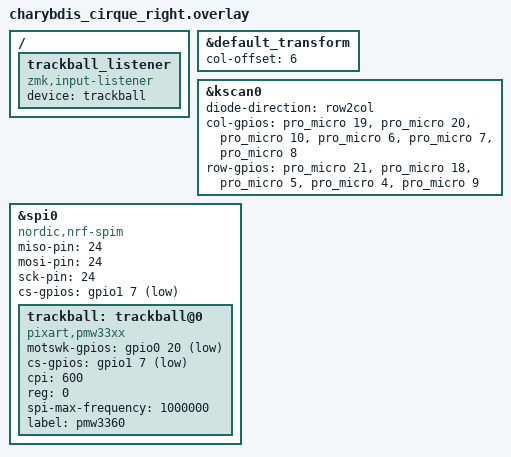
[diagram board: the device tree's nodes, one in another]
#include "charybdis_cirque.dtsi"

&default_transform {
    col-offset = <6>;
};

&kscan0 {
    diode-direction = "row2col";
    col-gpios
		= <&pro_micro 19 (GPIO_ACTIVE_HIGH | GPIO_PULL_DOWN)>
		, <&pro_micro 20 (GPIO_ACTIVE_HIGH | GPIO_PULL_DOWN)>
		, <&pro_micro 10 (GPIO_ACTIVE_HIGH | GPIO_PULL_DOWN)>
		, <&pro_micro 6 (GPIO_ACTIVE_HIGH | GPIO_PULL_DOWN)>
		, <&pro_micro 7 (GPIO_ACTIVE_HIGH | GPIO_PULL_DOWN)>
		, <&pro_micro 8 (GPIO_ACTIVE_HIGH | GPIO_PULL_DOWN)>
    ;
    row-gpios
		 	= <&pro_micro 21 GPIO_ACTIVE_HIGH>
		 	, <&pro_micro 18 GPIO_ACTIVE_HIGH>
		 	, <&pro_micro 5 GPIO_ACTIVE_HIGH>
		 	, <&pro_micro 4 GPIO_ACTIVE_HIGH>
		 	, <&pro_micro 9 GPIO_ACTIVE_HIGH>
    ;
};
// &nice_nano_spi {
//     status = "okay";
// };
// &trackpad {
//     status = "okay";
// };


/*
&pinctrl {
    spi0_default: spi0_default {
        group1 {
            psels = <NRF_PSEL(SPIM_SCK, 0, 8)>,
                <NRF_PSEL(SPIM_MOSI, 0, 17)>,
                <NRF_PSEL(SPIM_MISO, 0, 17)>;
        };
    };

    spi0_sleep: spi0_sleep {
        group1 {
            psels = <NRF_PSEL(SPIM_SCK, 0, 8)>,
                <NRF_PSEL(SPIM_MOSI, 0, 17)>,
                <NRF_PSEL(SPIM_MISO, 0, 17)>;
            low-power-enable;
        };
    };
};


&spi0 {
	compatible = "nordic,nrf-spim";
    status = "okay";

  pinctrl-0 = <&spi0_default>;
  pinctrl-1 = <&spi0_sleep>;
  pinctrl-names = "default", "sleep";


    cs-gpios = <&gpio1 7 GPIO_ACTIVE_LOW>; // P1.07

    trackball: trackball@0 {
        status = "okay";

        compatible = "pixart,pmw3360";
        irq-gpios = <&gpio0 20 GPIO_ACTIVE_LOW >; // 0.20

        reg = <0>;

        spi-max-frequency = <1000000>;
        label = "pmw3360";
    };
};


/ {
  trackball_listener {
    compatible = "zmk,input-listener";
    device = <&trackball>;
  };
};
*/

&spi0 {
	compatible = "nordic,nrf-spim";
    status = "okay";

    miso-pin = <24>; // P1.11
    mosi-pin = <24>; // P0.10
    sck-pin = <24>; // P1.13

    cs-gpios = <&gpio1 7 GPIO_ACTIVE_LOW>; // P1.07

    trackball: trackball@0 {
        status = "okay";
        compatible = "pixart,pmw33xx";
        motswk-gpios = <&gpio0 20 GPIO_ACTIVE_LOW>;  // P1.00 = 32 + 0
        cs-gpios = <&gpio1 7 GPIO_ACTIVE_LOW>;  // P1.07
        cpi = <600>;

        reg = <0>;

        spi-max-frequency = <1000000>;
        label = "pmw3360";
    };
};


/ {
  trackball_listener {
    compatible = "zmk,input-listener";
    device = <&trackball>;
  };
};



